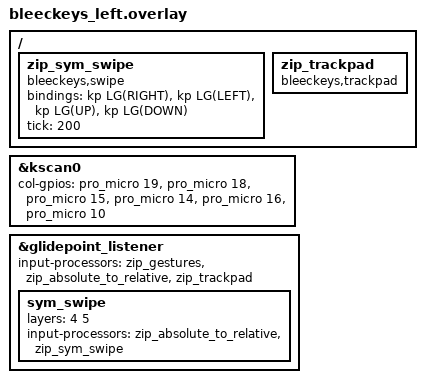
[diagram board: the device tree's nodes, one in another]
#include "bleeckeys.dtsi" // The shared dtsi file is included in the overlay
#include <dt-bindings/zmk/keys.h>

/ {
    // While SYM LEFT or SYM RIGHT (layers 4, 5) is held, a swipe taps Win + arrow in
    // its direction, once per touch. A held Shift is added by the OS as usual
    // (Win + Shift + arrow). tick: swipe length needed (pad is 1024). Driver: swipe.c
    zip_sym_swipe: zip_sym_swipe {
        compatible = "bleeckeys,swipe";
        #input-processor-cells = <0>;
        bindings = <&kp LG(RIGHT)>, <&kp LG(LEFT)>, <&kp LG(UP)>, <&kp LG(DOWN)>;
        tick = <200>;
    };

    // Tap to click, double tap, tap-and-hold drag, edge motion. Driver: trackpad.c
    zip_trackpad: zip_trackpad {
        compatible = "bleeckeys,trackpad";
        #input-processor-cells = <0>;
    };
};

// Label of the kscan node in the dtsi
&kscan0 {
    col-gpios
        = <&pro_micro 19 GPIO_ACTIVE_HIGH>
        , <&pro_micro 18 GPIO_ACTIVE_HIGH>
        , <&pro_micro 15 GPIO_ACTIVE_HIGH>
        , <&pro_micro 14 GPIO_ACTIVE_HIGH>
        , <&pro_micro 16 GPIO_ACTIVE_HIGH>
        , <&pro_micro 10 GPIO_ACTIVE_HIGH>
        ;
};

&glidepoint_listener {
    status = "okay";
    input-processors = <&zip_gestures &zip_absolute_to_relative &zip_trackpad>;

    sym_swipe {
        layers = <4 5>;
        input-processors = <&zip_absolute_to_relative &zip_sym_swipe>;
    };
};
